# EMU_PRM register map
Vendor: Texas Instruments
Peripheral module from a debugger description file (folder omap5430_ES2_PUBLIC).
Registers are 32-bit, access not given, reset 0x30000 unless marked. A register's access mark holds for its fields unless they carry their own. Offsets are as the file gives them; lines under a group give offsets from that group; [hi:lo] are bit positions; {n}, {i} and the like mark numbered series; 'fields as' and 'values as' point back to an identical list; <NAME> marks a mode.

## EMU_PRM
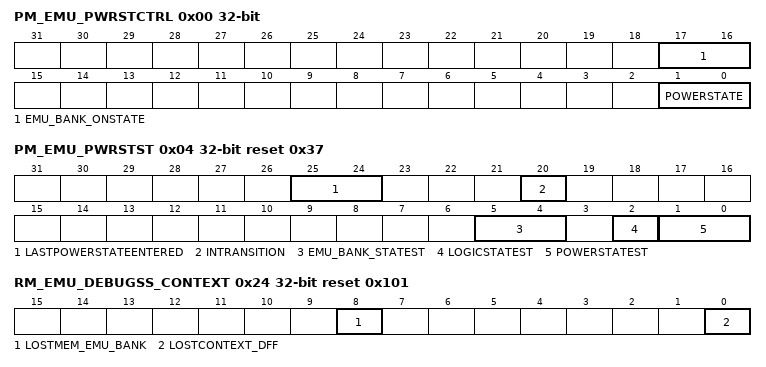
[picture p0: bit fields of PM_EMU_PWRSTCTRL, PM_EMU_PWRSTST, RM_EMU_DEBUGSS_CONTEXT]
0x00 PM_EMU_PWRSTCTRL ro — This register controls the EMU power state to reach upon a domain sleep transition
  [17:16] EMU_BANK_ONSTATE — EMU memory state when domain is ON.
    3=Mem_on (Memory bank is on when the domain is ON.)
  [1:0] POWERSTATE — Power state control
    0=OFF (Reserved)
0x04 PM_EMU_PWRSTST reset 0x37 — This register provides a status on the EMU domain current power state. [warm reset insensitive]
  [25:24] LASTPOWERSTATEENTERED — Last low power state entered. Set to 0x3 upon write of the same only. This register is intended for debug purpose only. Read 0x0: Reserved Read 0x1: Power domain was previously in RETENTION Read 0x2: Power domain was previously ON-INACTIVE Read 0x3: Power domain was previously ON-ACTIVE (access RW W1toSet)
  [20] INTRANSITION ro — Domain transition status
    0=No (No on-going transition on power domain); 1=Ongoing (Power domain transition is in progress.)
  [5:4] EMU_BANK_STATEST ro — EMU memory bank state status
    0=Mem_off (Reserved); 3=Mem_on (Memory is ON It is supplied by WKUP LDO)
  [2] LOGICSTATEST ro — Logic state status
    0=OFF (Logic in domain is OFF); 1=ON (Logic in domain is ON)
  [1:0] POWERSTATEST ro — Current power state status
    0=OFF (Reserved); 3=ON (Power domain is ON-ACTIVE)
0x24 RM_EMU_DEBUGSS_CONTEXT reset 0x101 — This register contains dedicated DEBUGSS context statuses. [warm reset insensitive]
  [8] LOSTMEM_EMU_BANK — Specify if memory-based context in EMU_BANK memory bank has been lost due to a previous power transition or other reset source. (access RW W1toClr)
    0=Maintained (Context has been maintained); 1=Lost (Context has been lost)
  [0] LOSTCONTEXT_DFF — Specify if DFF-based context has been lost due to a previous power transition or other reset source. (set upon assertion of EMU_RST signal) (access RW W1toClr)
    values as LOSTMEM_EMU_BANK
